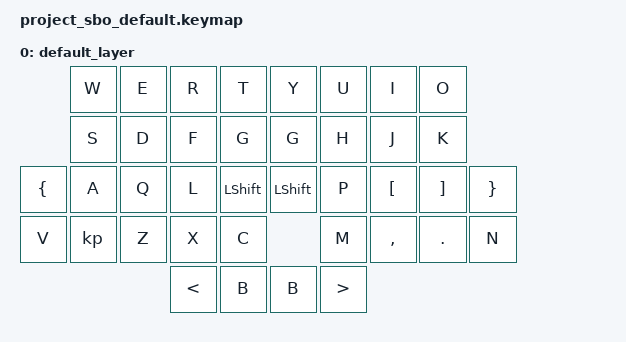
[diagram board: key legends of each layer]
/*
 * Copyright (c) 2022 The ZMK Contributors
 *
 * SPDX-License-Identifier: MIT
 */

#include <behaviors.dtsi>
#include <dt-bindings/zmk/keys.h>

#define DEF_L 0
//               |     W     |     E     |     R     |     T     |     Y     |     U     |     I     |     O     |
//               |     S     |     D     |     F     |     G     |     G     |     H     |     J     |     K     |
//    |     {    |     A     |     Q     |     L     |   SHIFT   |   SHIFT   |     P     |     [     |     ]     |     }     |
//    |     V    |     Z     |     X     |     C     |                       |     M     |     ,     |     .     |     N     |
//                                       |     <     |     B     |     B     |     >     |



/ {
    keymap {
        compatible = "zmk,keymap";

        default_layer {
            bindings = <
                     &kp W       &kp E       &kp R       &kp T       &kp Y       &kp U       &kp I       &kp O
                     &kp S       &kp D       &kp F       &kp G       &kp G       &kp H       &kp J       &kp K
         &kp LBRC    &kp A       &kp Q       &kp L     &kp LSHIFT &kp LSHIFT     &kp P      &kp LBKT   &kp RBKT     &kp RBRC
            &kp V    $kp Z       &kp X       &kp C                               &kp M      &kp COMMA     &kp DOT        &kp N
                                             &kp LT      &kp B       &kp B       &kp GT
                            >;
        };
    };
};
